# Cortex_M55 register map
Vendor: Arm Ltd.; Series: ARMv8.1-M Mainline; File version: 1.0.0
CPU: CM55 r0p0, little endian, MPU, FPU, double-precision FPU, DSP, 8 interrupt priority bits
Registers are 32-bit, read-write, reset 0x0 unless marked. A register's access mark holds for its fields unless they carry their own. Offsets are from the block's base; [hi:lo] are bit positions; {n}, {i} and the like mark numbered series.

## MEMSYSCTL — Memory System Control (Cortex-M55/M85/M52): ECC, cache and prefetcher control, TCM and P-AHB window enables, and the TCM Gate Units (ITGU/DTGU) that assign security attributes to TCM blocks.
Base 0xE001E000
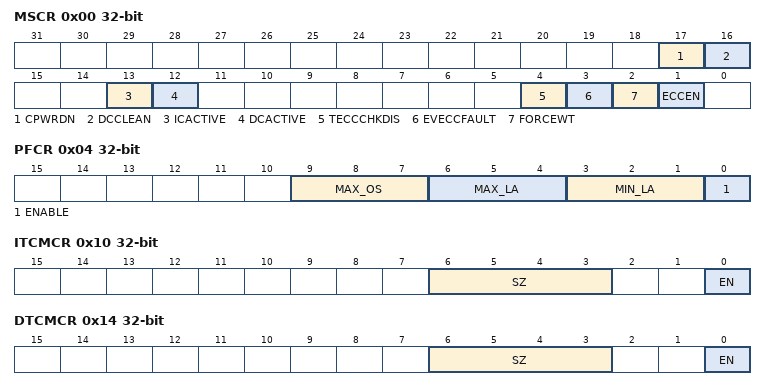
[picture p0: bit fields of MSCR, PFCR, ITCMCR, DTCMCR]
0x00 MSCR — Memory System Control Register: ECC enable, forced write-through, ECC fault reporting, TCM ECC checking and read-only cache status.
  [17] CPWRDN — Cache power-down: 1 = the cache RAMs may be powered down when the caches are disabled.
  [16] DCCLEAN ro — Data cache clean (read-only): 1 = no dirty lines.
  [13] ICACTIVE ro — Instruction cache active (read-only).
  [12] DCACTIVE ro — Data cache active (read-only): 1 = the D-cache is enabled and powered.
  [4] TECCCHKDIS — TCM ECC check disable: 1 = ECC on the TCMs is not checked (still generated).
  [3] EVECCFAULT — Enable ECC fault reporting: 1 = an uncorrectable ECC error raises a BusFault (with an error bank entry) instead of being silently poisoned.
  [2] FORCEWT — Force write-through: 1 = all cacheable data is cached write-through.
  [1] ECCEN — ECC enable for the caches and TCMs.
0x04 PFCR — Prefetcher Control Register: data prefetcher enable and look-ahead/outstanding limits.
  [9:7] MAX_OS — Maximum number of outstanding prefetches.
  [6:4] MAX_LA — Maximum look-ahead distance (cache lines).
  [3:1] MIN_LA — Minimum look-ahead distance (cache lines).
  [0] ENABLE — Data prefetcher enable.
0x10 ITCMCR — ITCM Control Register: enable and size of the instruction TCM.
  [6:3] SZ ro — TCM size: 0 = none, 3 = 4 KB, 4 = 8 KB, 5 = 16 KB, 6 = 32 KB, 7 = 64 KB, 8 = 128 KB, 9 = 256 KB, 10 = 512 KB, 11 = 1 MB, 12 = 2 MB, 13 = 4 MB, 14 = 8 MB, 15 = 16 MB (2^(SZ-1) KB). Read-only.
  [0] EN — ITCM enable: 1 = the ITCM responds to accesses in its address range.
0x14 DTCMCR — DTCM Control Register: enable and size of the data TCM.
  [6:3] SZ ro — TCM size: 0 = none, 3 = 4 KB, 4 = 8 KB, 5 = 16 KB, 6 = 32 KB, 7 = 64 KB, 8 = 128 KB, 9 = 256 KB, 10 = 512 KB, 11 = 1 MB, 12 = 2 MB, 13 = 4 MB, 14 = 8 MB, 15 = 16 MB (2^(SZ-1) KB). Read-only.
  [0] EN — DTCM enable: 1 = the DTCM responds to accesses in its address range.
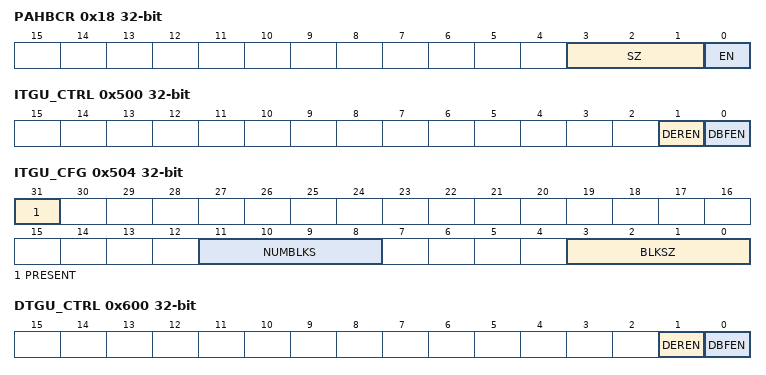
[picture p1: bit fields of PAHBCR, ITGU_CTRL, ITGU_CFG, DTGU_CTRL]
0x18 PAHBCR — P-AHB Control Register: enable and size of the peripheral AHB window.
  [3:1] SZ ro — P-AHB window size: 0 = disabled, 1 = 64 MB, 2 = 128 MB, 3 = 256 MB, 4 = 512 MB. Read-only.
  [0] EN — P-AHB enable: 1 = accesses in the P-AHB window use the peripheral AHB port instead of the AXI master.
0x500 ITGU_CTRL — ITCM Gate Unit Control Register: how ITGU security violations are reported.
  [1] DEREN — Debug error response enable: 1 = debugger accesses that violate the ITGU get an error response.
  [0] DBFEN — Data bus fault enable: 1 = an ITGU security violation raises a BusFault/SecureFault (0 = the access is RAZ/WI).
0x504 ITGU_CFG — ITCM Gate Unit Configuration Register: block size and count (read-only).
  [31] PRESENT — ITGU present.
  [11:8] NUMBLKS — Number of blocks: 2^NUMBLKS.
  [3:0] BLKSZ — Block size: 2^(BLKSZ+5) bytes per look-up-table bit.
{0x510+4i} ITGU_LUT{i} (i=0..15) — ITCM Gate Unit Look-Up Table n: bit k marks ITCM block 32n+k as Non-secure (0 = Secure).
  [31:0] LUT — Bit k: ITCM block 32n+k is Non-secure (1) or Secure (0).
0x600 DTGU_CTRL — DTCM Gate Unit Control Register: how DTGU security violations are reported.
  [1] DEREN — Debug error response enable: 1 = debugger accesses that violate the DTGU get an error response.
  [0] DBFEN — Data bus fault enable: 1 = a DTGU security violation raises a BusFault/SecureFault (0 = the access is RAZ/WI).
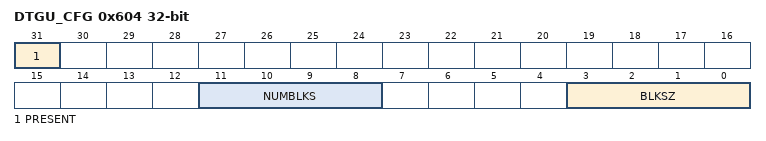
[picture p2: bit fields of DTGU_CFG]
0x604 DTGU_CFG — DTCM Gate Unit Configuration Register: block size and count (read-only).
  [31] PRESENT — DTGU present.
  [11:8] NUMBLKS — Number of blocks: 2^NUMBLKS.
  [3:0] BLKSZ — Block size: 2^(BLKSZ+5) bytes per look-up-table bit.
{0x610+4i} DTGU_LUT{i} (i=0..15) — DTCM Gate Unit Look-Up Table n: bit k marks DTCM block 32n+k as Non-secure (0 = Secure).
  [31:0] LUT — Bit k: DTCM block 32n+k is Non-secure (1) or Secure (0).

## Notices in the file
Copyright 2026 Arm Limited. Licensed under the Apache License, Version 2.0.
Copyright 2026 Arm Limited. Licensed under the Apache License, Version 2.0 (the "License");
you may not use this file except in compliance with the License. You may obtain a copy of the License at
https://www.apache.org/licenses/LICENSE-2.0
Unless required by applicable law or agreed to in writing, software
distributed under the License is distributed on an "AS IS" BASIS, WITHOUT WARRANTIES OR CONDITIONS OF ANY KIND,
either express or implied. See the License for the specific language governing permissions and limitations under the License.
